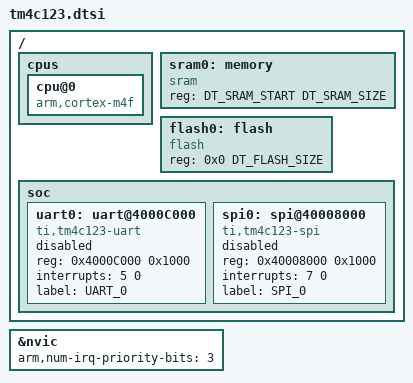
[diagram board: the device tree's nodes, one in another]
#include <arm/armv7-m.dtsi>
#include <ti/mem.h>

/ {
	cpus {
		cpu@0 {
			compatible = "arm,cortex-m4f";
		};
	};

	sram0: memory {
		compatible = "sram";
		reg = <DT_SRAM_START DT_SRAM_SIZE>;
	};

	flash0: flash {
		compatible = "flash";
		reg = <0x0 DT_FLASH_SIZE>;
	};

	soc {
		uart0: uart@4000C000 {
			compatible = "ti,tm4c123-uart";
			reg = <0x4000C000 0x1000>;
			interrupts = <5 0>; /* 5 = 21(TI uart interrupt num) - 16(zephyr), for compatible zephyr */
			interrupt-names = "status";
			status = "disabled";
			label = "UART_0";
		};

		spi0: spi@40008000 {
			compatible = "ti,tm4c123-spi";
			reg = <0x40008000 0x1000>;
			interrupts = <7 0>; /* 7 = 23(TI uart interrupt num) - 16(zephyr), for compatible zephyr */
			status = "disabled";
			label = "SPI_0";
		};
	};
};

&nvic {
	arm,num-irq-priority-bits = <3>;
};
